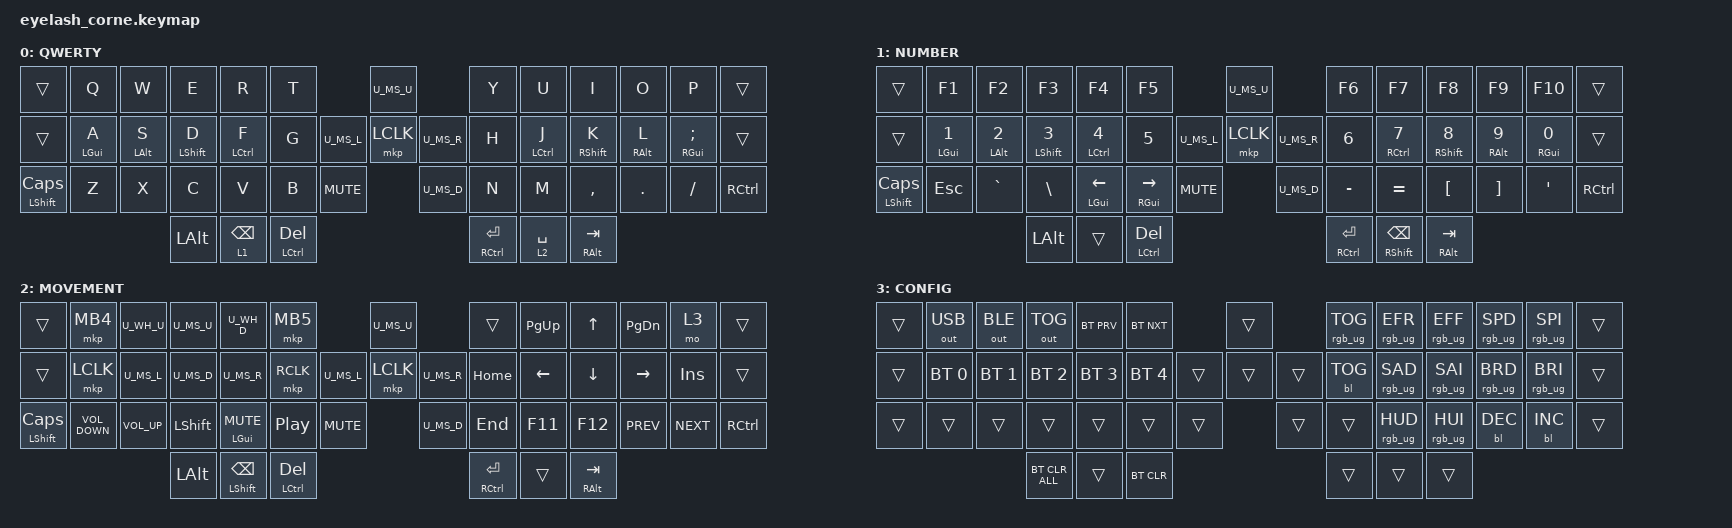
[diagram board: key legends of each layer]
#include <dt-bindings/zmk/mouse.h>
#include <input/processors.dtsi>

/* use helper macros to define left and right hand keys */

#include "zmk-helpers/key-labels/42.h"                                      // key-position labels
#include "zmk-helpers/helper.h"
#include <behaviors.dtsi>
#include <dt-bindings/zmk/backlight.h>
#include <dt-bindings/zmk/bt.h>
#include <dt-bindings/zmk/keys.h>
#include <dt-bindings/zmk/outputs.h>
#include <dt-bindings/zmk/pointing.h>
#include <dt-bindings/zmk/pointing.h>
#include <dt-bindings/zmk/pointing.h>
#include <dt-bindings/zmk/rgb.h>
#include "mouse.dtsi"


#define KEYS_L LT0 LT1 LT2 LT3 LT4 LT5 LM0 LM1 LM2 LM3 LM4 LM5 LB0 LB1 LB2 LB3 LB4 LB5  // left-hand keys
#define KEYS_R RT0 RT1 RT2 RT3 RT4 RT5 RM0 RM1 RM2 RM3 RM4 RM5 RB0 RB1 RB2 RB3 RB4 RB5  // right-hand keys
#define KEYS_T LH2 LH1 LH0 RH0 RH1 RH2                                      // thumb keys
#define HM_TAPPING_TERM 140
#define HM_TAPPING_TERM_FAST 140
#define HM_TAPPING_TERM_SLOW 200
#define HM_PRIOR_IDLE 90
#define HM_QUICK_TAP 120 


&lt {
    tapping-term-ms = <HM_TAPPING_TERM>;
};

/ {
    behaviors {
        // Positional Homerow mods
        // Homerow mods that prevent accidental activations when rolling keys,
        // such as when typing `st` or `ne` on colemak-dh layouts or `as` on
        // qwerty.
        //
        // Works by only allowing a mod to activate within tapping-term if
        // it's on the opposite side of the keyboard or on the same side thumb
        // keys.
        // Further optimization using urob's timerless homerow mods method:
        // https://github.com/urob/zmk-config#timeless-homerow-mods

        hm_l: homerow_mods_left {
            compatible = "zmk,behavior-hold-tap";
            #binding-cells = <2>;
            bindings = <&kp>, <&kp>;

            //flavor = "balanced";
            flavor = "tap-preferred";
            tapping-term-ms = <HM_TAPPING_TERM>;
            quick-tap-ms = <HM_QUICK_TAP>;                // repeat on tap-into-hold
            require-prior-idle-ms = <HM_PRIOR_IDLE>;
            hold-trigger-key-positions = <KEYS_R KEYS_T>;
            hold-trigger-on-release;
            //retro-tap;
        };

        hm_r: homerow_mods_right {
            compatible = "zmk,behavior-hold-tap";
            #binding-cells = <2>;
            bindings = <&kp>, <&kp>;

            //flavor = "balanced";
            flavor = "tap-preferred";
            tapping-term-ms = <HM_TAPPING_TERM>;
            quick-tap-ms = <HM_QUICK_TAP>;
            require-prior-idle-ms = <HM_PRIOR_IDLE>;
            hold-trigger-key-positions = <KEYS_L KEYS_T>;
            hold-trigger-on-release;
            //retro-tap;
        };

        // Positional Homerow mods for shift
        // Use faster tapping term and disable some features that may
        // cause false negatives.

        hm_shift_l: hm_shift_l {
            compatible = "zmk,behavior-hold-tap";
            #binding-cells = <2>;
            bindings = <&kp>, <&kp>;

            //flavor = "balanced";
            flavor = "tap-preferred";
            tapping-term-ms = <HM_TAPPING_TERM_FAST>;
            quick-tap-ms = <HM_QUICK_TAP>;
            require-prior-idle-ms = <HM_PRIOR_IDLE>;
            hold-trigger-key-positions = <KEYS_R KEYS_T>;
            hold-trigger-on-release;
            //retro-tap;
        };

        hm_shift_r: hm_shift_r {
            compatible = "zmk,behavior-hold-tap";
            #binding-cells = <2>;
            bindings = <&kp>, <&kp>;

            //flavor = "balanced";
            flavor = "tap-preferred";
            tapping-term-ms = <HM_TAPPING_TERM_FAST>;
            quick-tap-ms = <HM_QUICK_TAP>;
            require-prior-idle-ms = <HM_PRIOR_IDLE>;
            hold-trigger-key-positions = <KEYS_L KEYS_T>;
            hold-trigger-on-release;
            //retro-tap;
        };

        hm_alt_l: hm_alt_l {
            compatible = "zmk,behavior-hold-tap";
            #binding-cells = <2>;
            bindings = <&kp>, <&kp>;

            //flavor = "balanced";
            flavor = "tap-preferred";
            tapping-term-ms = <HM_TAPPING_TERM_SLOW>;
            quick-tap-ms = <HM_QUICK_TAP>;
            require-prior-idle-ms = <HM_PRIOR_IDLE>;
            hold-trigger-key-positions = <KEYS_R KEYS_T>;
            hold-trigger-on-release;
            //retro-tap;
        };

        hm_alt_r: hm_alt_r {
            compatible = "zmk,behavior-hold-tap";
            #binding-cells = <2>;
            bindings = <&kp>, <&kp>;

            //flavor = "balanced";
            flavor = "tap-preferred";
            tapping-term-ms = <HM_TAPPING_TERM_SLOW>;
            quick-tap-ms = <HM_QUICK_TAP>;
            require-prior-idle-ms = <HM_PRIOR_IDLE>;
            hold-trigger-key-positions = <KEYS_L KEYS_T>;
            hold-trigger-on-release;
            //retro-tap;
        };

        /*
         * Non-Positional Homerow Mods
         * Used for &mm_grescm_gui behavior on left hand.
         *
         * Usage: &hm LSHFT T
         * Tap: T
         * Tap-Tap-Hold: Repeat T
         * Hold: LSHIFT
         */

        hm: homerow_mods {
            compatible = "zmk,behavior-hold-tap";
            #binding-cells = <2>;
            bindings = <&kp>, <&kp>;

            flavor = "balanced";
            tapping-term-ms = <HM_TAPPING_TERM>;
            quick-tap-ms = <HM_QUICK_TAP>;
            retro-tap;
        };

    
      
    };

    rgb_encoder: rgb_encoder {
        compatible = "zmk,behavior-sensor-rotate";
        #sensor-binding-cells = <0>;
        bindings = <&rgb_ug RGB_BRI>, <&rgb_ug RGB_BRD>;
    };

    scroll_encoder: scroll_encoder {
        compatible = "zmk,behavior-sensor-rotate";
        #sensor-binding-cells = <0>;
        bindings = <&msc SCRL_DOWN>, <&msc SCRL_UP>;

        tap-ms = <30>;
        label = "SCROLL_ENCODER";
    };

    scroll_encoder_lr: scroll_encoder_lr {
            compatible = "zmk,behavior-sensor-rotate";
            #sensor-binding-cells = <0>;
            bindings = <&msc SCRL_RIGHT>, <&msc SCRL_LEFT>;

            tap-ms = <30>;
            label = "SCROLL_ENCODER_LR";
        };

    keymap {
        compatible = "zmk,keymap";

        default_layer {
            display-name = "QWERTY";
            bindings = <
&trans  &kp Q         &kp W             &kp E               &kp R            &kp T                                                   U_MS_U                    &kp Y              &kp U          &kp I           &kp O              &kp P                 &trans
&trans    &hm_shift_l LGUI A  &hm_alt_l LEFT_ALT S  &hm_shift_l LEFT_SHIFT D  &hm_l LCTRL F    &kp G                                   U_MS_L &mkp LCLK       U_MS_R  &kp H              &hm_r LCTRL J  &hm_shift_r RSHIFT K  &hm_alt_r RIGHT_ALT L  &hm_shift_r RIGHT_GUI SEMI  &trans
&hm_shift_l LEFT_SHIFT CAPS  &kp Z         &kp X             &kp C               &kp V            &kp B                      &kp C_MUTE                   U_MS_D                  &kp N              &kp M          &kp COMMA       &kp DOT            &kp FSLH              &kp RCTRL
                                        &kp LEFT_ALT        &lt 1 BACKSPACE  &hm_l LEFT_CONTROL DELETE                                                                 &hm_r RCTRL ENTER  &lt 2 SPACE    &hm_alt_r RALT TAB
            >;

            sensor-bindings = <&scroll_encoder_lr>;
        };

        lower_layer {
            display-name = "NUMBER";
            bindings = <
&trans  &kp F1  &kp F2                   &kp F3                   &kp F4                     &kp F5                                                                    U_MS_U        &kp F6             &kp F7             &kp F8                       &kp F9               &kp F10             &trans
&trans  &hm_shift_l LEFT_GUI NUMBER_1  &hm_alt_l LEFT_ALT NUMBER_2  &hm_shift_l LEFT_SHIFT NUMBER_3  &hm_l LEFT_CONTROL NUMBER_4  &kp N5                              U_MS_L &mkp LCLK       U_MS_R  &kp NUMBER_6       &hm_r RCTRL N7               &hm_shift_r RIGHT_SHIFT N8  &hm_alt_r RIGHT_ALT N9  &hm_shift_r RIGHT_GUI N0  &trans             
&hm_shift_l LEFT_SHIFT CAPS   &kp ESCAPE               &kp GRAVE                &kp BACKSLASH              &hm_l LGUI LEFT_ARROW        &hm_l RIGHT_GUI RIGHT  &kp C_MUTE                   U_MS_D                  &kp MINUS          &kp EQUAL                    &kp LEFT_BRACKET     &kp RIGHT_BRACKET   &kp SINGLE_QUOTE    &kp RCTRL
                                                          &kp LEFT_ALT               &trans                       &hm_l LCTRL DELETE                                                                    &hm_r RCTRL ENTER  &hm_shift_r RIGHT_SHIFT BACKSPACE  &hm_alt_r RIGHT_ALT TAB
            >;

            sensor-bindings =<&inc_dec_kp C_VOLUME_UP C_VOLUME_DOWN>;
        };

        raise_layer {
            display-name = "MOVEMENT";
            bindings = <
&trans  &mkp MB4           U_WH_U    U_MS_U   U_WH_D              &mkp MB5                                             U_MS_U                    &trans             &kp PAGE_UP  &kp UP_ARROW         &kp PAGE_DOWN       &mo 3 &trans
&trans  &mkp LCLK         U_MS_L U_MS_D U_MS_R             &mkp RCLK                            U_MS_L &mkp LCLK       U_MS_R  &kp HOME           &kp LEFT     &kp DOWN             &kp RIGHT      &kp INSERT  &trans
&hm_shift_l LEFT_SHIFT CAPS  &kp C_VOLUME_DOWN  &kp C_VOLUME_UP  &kp LEFT_SHIFT  &hm_shift_l LEFT_GUI C_MUTE                  &kp C_PLAY_PAUSE        &kp C_MUTE                   U_MS_D                  &kp END            &kp F11 &kp F12               &kp C_PREV     &kp C_NEXT  &kp RCTRL
                                            &kp LEFT_ALT    &hm_shift_l LEFT_SHIFT BACKSPACE  &hm_l LEFT_CONTROL DEL                                                                 &hm_r RCTRL ENTER  &trans       &hm_alt_r RIGHT_ALT TAB
            >;

            sensor-bindings = <&scroll_encoder>;
        };

        layer_3 {
            display-name = "CONFIG";
            bindings = <
&trans  &out OUT_USB  &out OUT_BLE  &out OUT_TOG    &bt BT_PRV    &bt BT_NXT                      &trans          &rgb_ug RGB_TOG  &rgb_ug RGB_EFR  &rgb_ug RGB_EFF  &rgb_ug RGB_SPD  &rgb_ug RGB_SPI  &trans
&trans  &bt BT_SEL 0  &bt BT_SEL 1  &bt BT_SEL 2    &bt BT_SEL 3  &bt BT_SEL 4            &trans  &trans  &trans  &bl BL_TOG       &rgb_ug RGB_SAD  &rgb_ug RGB_SAI  &rgb_ug RGB_BRD  &rgb_ug RGB_BRI  &trans
&trans  &trans        &trans        &trans          &trans        &trans        &trans            &trans          &trans           &rgb_ug RGB_HUD  &rgb_ug RGB_HUI  &bl BL_DEC       &bl BL_INC       &trans
                                    &bt BT_CLR_ALL  &trans        &bt BT_CLR                                      &trans           &trans           &trans
            >;
        };
    };
};
